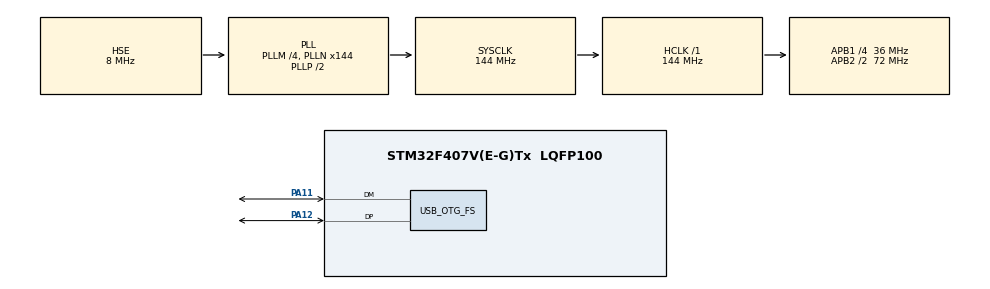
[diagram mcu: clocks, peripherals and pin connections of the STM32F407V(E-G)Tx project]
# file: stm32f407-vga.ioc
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Mcu.Family=STM32F4
Mcu.Name=STM32F407V(E-G)Tx
Mcu.Package=LQFP100
NVIC.OTG_FS_IRQn=true\:0\:0\:false\:false\:true\:false\:true
NVIC.PriorityGroup=NVIC_PRIORITYGROUP_4
PA11.Mode=Device_Only
PA11.Signal=USB_OTG_FS_DM
PA12.Mode=Device_Only
PA12.Signal=USB_OTG_FS_DP
PC14-OSC32_IN.Mode=LSE-External-Oscillator
PC14-OSC32_IN.Signal=RCC_OSC32_IN
PC15-OSC32_OUT.Mode=LSE-External-Oscillator
PC15-OSC32_OUT.Signal=RCC_OSC32_OUT
PH0-OSC_IN.Mode=HSE-External-Oscillator
PH0-OSC_IN.Signal=RCC_OSC_IN
PH1-OSC_OUT.Mode=HSE-External-Oscillator
PH1-OSC_OUT.Signal=RCC_OSC_OUT
ProjectManager.HeapSize=0x200
ProjectManager.StackSize=0x400
ProjectManager.TargetToolchain=Makefile
RCC.48MHZClocksFreq_Value=48000000
RCC.AHBFreq_Value=144000000
RCC.APB1CLKDivider=RCC_HCLK_DIV4
RCC.APB1Freq_Value=36000000
RCC.APB1TimFreq_Value=72000000
RCC.APB2CLKDivider=RCC_HCLK_DIV2
RCC.APB2Freq_Value=72000000
RCC.APB2TimFreq_Value=144000000
RCC.CortexFreq_Value=144000000
RCC.HCLKFreq_Value=144000000
RCC.HSE_VALUE=8000000
RCC.HSI_VALUE=16000000
RCC.PLLM=4
RCC.PLLN=144
RCC.PLLQ=6
RCC.RCC_RTC_Clock_Source=RCC_RTCCLKSOURCE_LSE
RCC.RCC_RTC_Clock_SourceVirtual=RCC_RTCCLKSOURCE_LSE
RCC.SYSCLKFreq_VALUE=144000000
RCC.SYSCLKSource=RCC_SYSCLKSOURCE_PLLCLK
RCC.VCOOutputFreq_Value=288000000
USB_DEVICE.CLASS_NAME_FS=CDC
USB_DEVICE.VirtualMode-CDC_FS=Cdc
USB_DEVICE.VirtualModeFS=Cdc_FS
USB_OTG_FS.VirtualMode=Device_Only
VP_RTC_VS_RTC_Activate.Mode=RTC_Enabled
VP_USB_DEVICE_VS_USB_DEVICE_CDC_FS.Mode=CDC_FS
board=custom

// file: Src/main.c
/* USER CODE BEGIN Header */
/**
  ******************************************************************************
  * @file           : main.c
  * @brief          : Main program body
  ******************************************************************************
  * @attention
  *
  * <h2><center>&copy; Copyright (c) 2020 STMicroelectronics.
  * All rights reserved.</center></h2>
  *
  * This software component is licensed by ST under Ultimate Liberty license
  * SLA0044, the "License"; You may not use this file except in compliance with
  * the License. You may obtain a copy of the License at:
  *                             www.st.com/SLA0044
  *
  ******************************************************************************
  */
/* USER CODE END Header */
#include "main.h"
#include "usb_device.h"

/* USER CODE BEGIN Includes */
#include "startup.h"
/* USER CODE END Includes */

RTC_HandleTypeDef hrtc;

/* USER CODE BEGIN PV */
/* Private variables ---------------------------------------------------------*/

/* USER CODE END PV */

void SystemClock_Config(void);
static void MX_GPIO_Init(void);
static void MX_RTC_Init(void);
/* USER CODE BEGIN PFP */
/* Private function prototypes -----------------------------------------------*/

/* USER CODE END PFP */

int main(void)
{

  /* MCU Configuration--------------------------------------------------------*/

  /* Reset of all peripherals, Initializes the Flash interface and the Systick. */
  HAL_Init();

  /* Configure the system clock */
  SystemClock_Config();

  /* USER CODE BEGIN SysInit */
  initialize();
  /* USER CODE END SysInit */

  /* Initialize all configured peripherals */
  MX_GPIO_Init();
  MX_RTC_Init();
  MX_USB_DEVICE_Init();
  /* USER CODE BEGIN 2 */
  setup();
  /* USER CODE END 2 */

  /* Infinite loop */
  /* USER CODE BEGIN WHILE */
  while (1)
  {
	  loop();
    /* USER CODE END WHILE */

  }
}

void SystemClock_Config(void)
{
  RCC_OscInitTypeDef RCC_OscInitStruct = {0};
  RCC_ClkInitTypeDef RCC_ClkInitStruct = {0};

  /** Configure the main internal regulator output voltage
  */
  __HAL_RCC_PWR_CLK_ENABLE();
  __HAL_PWR_VOLTAGESCALING_CONFIG(PWR_REGULATOR_VOLTAGE_SCALE1);
  /** Initializes the RCC Oscillators according to the specified parameters
  * in the RCC_OscInitTypeDef structure.
  */
  RCC_OscInitStruct.OscillatorType = RCC_OSCILLATORTYPE_HSE|RCC_OSCILLATORTYPE_LSE;
  RCC_OscInitStruct.HSEState = RCC_HSE_ON;
  RCC_OscInitStruct.LSEState = RCC_LSE_ON;
  RCC_OscInitStruct.PLL.PLLState = RCC_PLL_ON;
  RCC_OscInitStruct.PLL.PLLSource = RCC_PLLSOURCE_HSE;
  RCC_OscInitStruct.PLL.PLLM = 4;
  RCC_OscInitStruct.PLL.PLLN = 144;
  RCC_OscInitStruct.PLL.PLLP = RCC_PLLP_DIV2;
  RCC_OscInitStruct.PLL.PLLQ = 6;
  if (HAL_RCC_OscConfig(&RCC_OscInitStruct) != HAL_OK)
  {
    Error_Handler();
  }
  /** Initializes the CPU, AHB and APB buses clocks
  */
  RCC_ClkInitStruct.ClockType = RCC_CLOCKTYPE_HCLK|RCC_CLOCKTYPE_SYSCLK
                              |RCC_CLOCKTYPE_PCLK1|RCC_CLOCKTYPE_PCLK2;
  RCC_ClkInitStruct.SYSCLKSource = RCC_SYSCLKSOURCE_PLLCLK;
  RCC_ClkInitStruct.AHBCLKDivider = RCC_SYSCLK_DIV1;
  RCC_ClkInitStruct.APB1CLKDivider = RCC_HCLK_DIV4;
  RCC_ClkInitStruct.APB2CLKDivider = RCC_HCLK_DIV2;

  if (HAL_RCC_ClockConfig(&RCC_ClkInitStruct, FLASH_LATENCY_4) != HAL_OK)
  {
    Error_Handler();
  }
}

static void MX_RTC_Init(void)
{

  /** Initialize RTC Only
  */
  hrtc.Instance = RTC;
  hrtc.Init.HourFormat = RTC_HOURFORMAT_24;
  hrtc.Init.AsynchPrediv = 127;
  hrtc.Init.SynchPrediv = 255;
  hrtc.Init.OutPut = RTC_OUTPUT_DISABLE;
  hrtc.Init.OutPutPolarity = RTC_OUTPUT_POLARITY_HIGH;
  hrtc.Init.OutPutType = RTC_OUTPUT_TYPE_OPENDRAIN;
  if (HAL_RTC_Init(&hrtc) != HAL_OK)
  {
    Error_Handler();
  }

}

static void MX_GPIO_Init(void)
{

  /* GPIO Ports Clock Enable */
  __HAL_RCC_GPIOC_CLK_ENABLE();
  __HAL_RCC_GPIOH_CLK_ENABLE();
  __HAL_RCC_GPIOA_CLK_ENABLE();

}

void Error_Handler(void)
{
  while(1)
  {
  }
}

/************************ (C) COPYRIGHT STMicroelectronics *****END OF FILE****/
